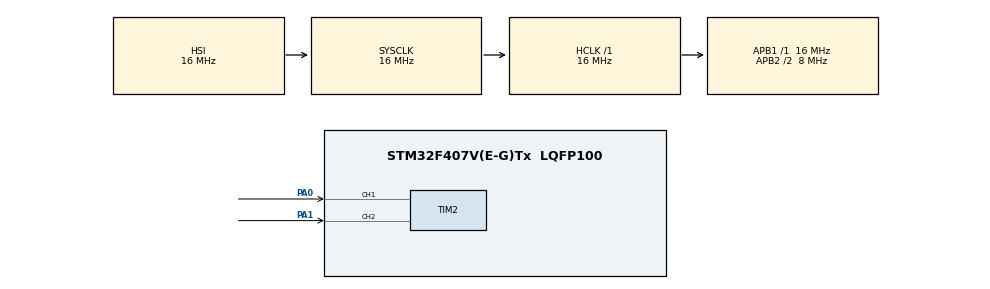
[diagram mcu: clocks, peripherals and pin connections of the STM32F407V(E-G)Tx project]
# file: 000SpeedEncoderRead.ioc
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Mcu.Family=STM32F4
Mcu.Name=STM32F407V(E-G)Tx
Mcu.Package=LQFP100
NVIC.PriorityGroup=NVIC_PRIORITYGROUP_0
NVIC.TIM1_UP_TIM10_IRQn=true\:0\:0\:false\:false\:true\:true\:true\:true
NVIC.TIM2_IRQn=true\:0\:0\:false\:false\:true\:true\:true\:true
PA0-WKUP.Signal=S_TIM2_CH1_ETR
PA1.Signal=S_TIM2_CH2
PA13.Mode=Serial_Wire
PA13.Signal=SYS_JTMS-SWDIO
PA14.Mode=Serial_Wire
PA14.Signal=SYS_JTCK-SWCLK
PH0-OSC_IN.Mode=HSE-External-Oscillator
PH0-OSC_IN.Signal=RCC_OSC_IN
PH1-OSC_OUT.Mode=HSE-External-Oscillator
PH1-OSC_OUT.Signal=RCC_OSC_OUT
ProjectManager.HeapSize=0x200
ProjectManager.StackSize=0x400
ProjectManager.TargetToolchain=STM32CubeIDE
RCC.48MHZClocksFreq_Value=48000000
RCC.AHBFreq_Value=16000000
RCC.APB1Freq_Value=16000000
RCC.APB1TimFreq_Value=16000000
RCC.APB2CLKDivider=RCC_HCLK_DIV2
RCC.APB2Freq_Value=8000000
RCC.APB2TimFreq_Value=16000000
RCC.CortexFreq_Value=16000000
RCC.HCLKFreq_Value=16000000
RCC.HSE_VALUE=8000000
RCC.HSI_VALUE=16000000
RCC.PLLM=8
RCC.PLLN=336
RCC.PLLQ=7
RCC.PLLSourceVirtual=RCC_PLLSOURCE_HSE
RCC.SYSCLKFreq_VALUE=16000000
RCC.VCOOutputFreq_Value=336000000
SH.S_TIM2_CH1_ETR.0=TIM2_CH1,Encoder_Interface
SH.S_TIM2_CH2.0=TIM2_CH2,Encoder_Interface
TIM1.Period=19999
TIM1.Prescaler=799
TIM2.EncoderMode=TIM_ENCODERMODE_TI12
TIM2.IC1Polarity=TIM_ICPOLARITY_FALLING
TIM2.IC2Polarity=TIM_ICPOLARITY_FALLING
VP_TIM1_VS_ClockSourceINT.Mode=Internal
board=STM32F407G-DISC1

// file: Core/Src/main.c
/* USER CODE BEGIN Header */
/**
  ******************************************************************************
  * @file           : main.c
  * @brief          : Main program body
  ******************************************************************************
  * @attention
  *
  * Copyright (c) 2022 STMicroelectronics.
  * All rights reserved.
  *
  * This software is licensed under terms that can be found in the LICENSE file
  * in the root directory of this software component.
  * If no LICENSE file comes with this software, it is provided AS-IS.
  *
  ******************************************************************************
  */
/* USER CODE END Header */
#include "main.h"

/* USER CODE BEGIN PM */

#define Diameter 64
#define Gear     30
#define MotorPulsePR 96
#define k_RPStokmh 0.001885

/* USER CODE END PM */

TIM_HandleTypeDef htim1;
TIM_HandleTypeDef htim2;

int counter ;

int preCounter;

int RPS ;

int speed;

void SystemClock_Config(void);
static void MX_GPIO_Init(void);
static void MX_TIM1_Init(void);
static void MX_TIM2_Init(void);

/* USER CODE BEGIN 0 */

void HAL_TIM_PeriodElapsedCallback(TIM_HandleTypeDef *htim)
{
//	counter = 0;
//	TIM2->CNT = 0;
	counter = __HAL_TIM_GET_COUNTER(&htim2);
	RPS = (counter - preCounter) / MotorPulsePR;
	preCounter = counter;
}

/* USER CODE END 0 */

int main(void)
{

  /* MCU Configuration--------------------------------------------------------*/

  /* Reset of all peripherals, Initializes the Flash interface and the Systick. */
  HAL_Init();

  /* Configure the system clock */
  SystemClock_Config();

  /* Initialize all configured peripherals */
  MX_GPIO_Init();
  MX_TIM1_Init();
  MX_TIM2_Init();
  /* USER CODE BEGIN 2 */

  HAL_TIM_Encoder_Start_IT(&htim2, TIM_CHANNEL_ALL);
  HAL_TIM_Base_Start_IT(&htim1);
  /* USER CODE END 2 */

  /* Infinite loop */
  while (1)
  {

	  speed = ( Diameter*RPS*60*k_RPStokmh ) / Gear;

  }
}

void SystemClock_Config(void)
{
  RCC_OscInitTypeDef RCC_OscInitStruct = {0};
  RCC_ClkInitTypeDef RCC_ClkInitStruct = {0};

  /** Configure the main internal regulator output voltage
  */
  __HAL_RCC_PWR_CLK_ENABLE();
  __HAL_PWR_VOLTAGESCALING_CONFIG(PWR_REGULATOR_VOLTAGE_SCALE1);

  /** Initializes the RCC Oscillators according to the specified parameters
  * in the RCC_OscInitTypeDef structure.
  */
  RCC_OscInitStruct.OscillatorType = RCC_OSCILLATORTYPE_HSI;
  RCC_OscInitStruct.HSIState = RCC_HSI_ON;
  RCC_OscInitStruct.HSICalibrationValue = RCC_HSICALIBRATION_DEFAULT;
  RCC_OscInitStruct.PLL.PLLState = RCC_PLL_NONE;
  if (HAL_RCC_OscConfig(&RCC_OscInitStruct) != HAL_OK)
  {
    Error_Handler();
  }

  /** Initializes the CPU, AHB and APB buses clocks
  */
  RCC_ClkInitStruct.ClockType = RCC_CLOCKTYPE_HCLK|RCC_CLOCKTYPE_SYSCLK
                              |RCC_CLOCKTYPE_PCLK1|RCC_CLOCKTYPE_PCLK2;
  RCC_ClkInitStruct.SYSCLKSource = RCC_SYSCLKSOURCE_HSI;
  RCC_ClkInitStruct.AHBCLKDivider = RCC_SYSCLK_DIV1;
  RCC_ClkInitStruct.APB1CLKDivider = RCC_HCLK_DIV1;
  RCC_ClkInitStruct.APB2CLKDivider = RCC_HCLK_DIV2;

  if (HAL_RCC_ClockConfig(&RCC_ClkInitStruct, FLASH_LATENCY_0) != HAL_OK)
  {
    Error_Handler();
  }
}

static void MX_TIM1_Init(void)
{

  TIM_ClockConfigTypeDef sClockSourceConfig = {0};
  TIM_MasterConfigTypeDef sMasterConfig = {0};

  htim1.Instance = TIM1;
  htim1.Init.Prescaler = 799;
  htim1.Init.CounterMode = TIM_COUNTERMODE_UP;
  htim1.Init.Period = 19999;
  htim1.Init.ClockDivision = TIM_CLOCKDIVISION_DIV1;
  htim1.Init.RepetitionCounter = 0;
  htim1.Init.AutoReloadPreload = TIM_AUTORELOAD_PRELOAD_DISABLE;
  if (HAL_TIM_Base_Init(&htim1) != HAL_OK)
  {
    Error_Handler();
  }
  sClockSourceConfig.ClockSource = TIM_CLOCKSOURCE_INTERNAL;
  if (HAL_TIM_ConfigClockSource(&htim1, &sClockSourceConfig) != HAL_OK)
  {
    Error_Handler();
  }
  sMasterConfig.MasterOutputTrigger = TIM_TRGO_RESET;
  sMasterConfig.MasterSlaveMode = TIM_MASTERSLAVEMODE_DISABLE;
  if (HAL_TIMEx_MasterConfigSynchronization(&htim1, &sMasterConfig) != HAL_OK)
  {
    Error_Handler();
  }

}

static void MX_TIM2_Init(void)
{

  TIM_Encoder_InitTypeDef sConfig = {0};
  TIM_MasterConfigTypeDef sMasterConfig = {0};

  htim2.Instance = TIM2;
  htim2.Init.Prescaler = 0;
  htim2.Init.CounterMode = TIM_COUNTERMODE_UP;
  htim2.Init.Period = 4294967295;
  htim2.Init.ClockDivision = TIM_CLOCKDIVISION_DIV1;
  htim2.Init.AutoReloadPreload = TIM_AUTORELOAD_PRELOAD_DISABLE;
  sConfig.EncoderMode = TIM_ENCODERMODE_TI12;
  sConfig.IC1Polarity = TIM_ICPOLARITY_FALLING;
  sConfig.IC1Selection = TIM_ICSELECTION_DIRECTTI;
  sConfig.IC1Prescaler = TIM_ICPSC_DIV1;
  sConfig.IC1Filter = 0;
  sConfig.IC2Polarity = TIM_ICPOLARITY_FALLING;
  sConfig.IC2Selection = TIM_ICSELECTION_DIRECTTI;
  sConfig.IC2Prescaler = TIM_ICPSC_DIV1;
  sConfig.IC2Filter = 0;
  if (HAL_TIM_Encoder_Init(&htim2, &sConfig) != HAL_OK)
  {
    Error_Handler();
  }
  sMasterConfig.MasterOutputTrigger = TIM_TRGO_RESET;
  sMasterConfig.MasterSlaveMode = TIM_MASTERSLAVEMODE_DISABLE;
  if (HAL_TIMEx_MasterConfigSynchronization(&htim2, &sMasterConfig) != HAL_OK)
  {
    Error_Handler();
  }

}

static void MX_GPIO_Init(void)
{

  /* GPIO Ports Clock Enable */
  __HAL_RCC_GPIOH_CLK_ENABLE();
  __HAL_RCC_GPIOA_CLK_ENABLE();

}

void Error_Handler(void)
{
  __disable_irq();
  while (1)
  {
  }
}
